VERSION ""

NS_ :

BS_:

BU_:

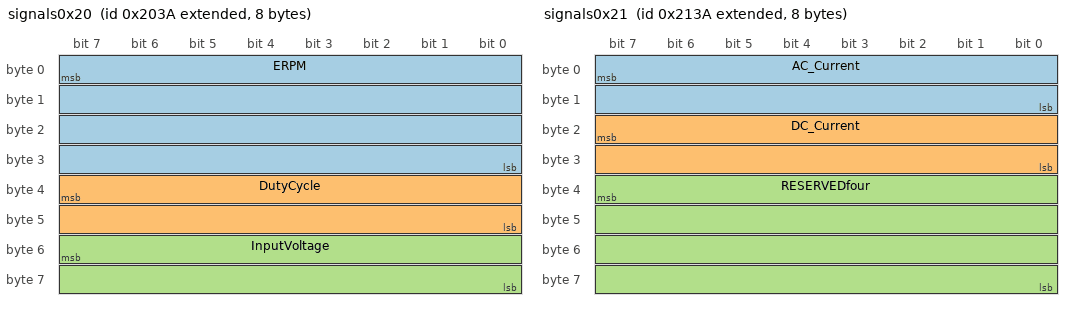
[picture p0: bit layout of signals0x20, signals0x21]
BO_ 2147491898 signals0x20: 8 Vector__XXX
	SG_ ERPM : 7|32@0+ (1,0) [-2147483648|2147483647] "ERPM" Vector__XXX
	SG_ DutyCycle : 39|16@0+ (0.1,0) [-3276.8|3276.7] "%" Vector__XXX
	SG_ InputVoltage : 55|16@0+ (1,0) [-32768|32767] "V" Vector__XXX

BO_ 2147492154 signals0x21: 8 Vector__XXX
	SG_ AC_Current : 7|16@0+ (0.1,0) [-3276.8|3276.7] "Apk" Vector__XXX
	SG_ DC_Current : 23|16@0+ (0.1,0) [-3276.8|3276.7] "Adc" Vector__XXX
	SG_ RESERVEDfour : 39|32@0+ (0,0) [0|0] "" Vector__XXX

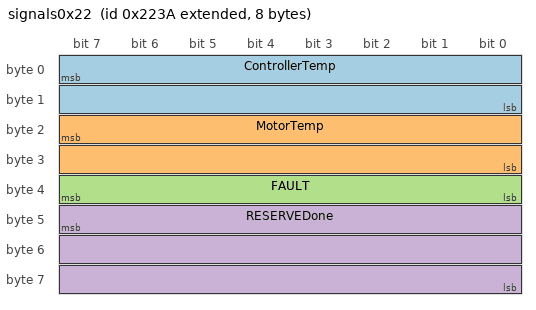
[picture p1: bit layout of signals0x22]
BO_ 2147492410 signals0x22: 8 Vector__XXX
	SG_ ControllerTemp : 7|16@0+ (0.1,0) [-3276.8|3276.7] "°C" Vector__XXX
	SG_ MotorTemp : 23|16@0+ (0.1,0) [-3276.8|3276.7] "°C" Vector__XXX
	SG_ FAULT : 39|8@0+ (1,0) [0|255] "#" Vector__XXX
	SG_ RESERVEDone : 47|24@0+ (0,0) [0|0] "" Vector__XXX

BO_ 2147492666 signals0x23: 8 Vector__XXX
	SG_ FOC_Id : 7|32@0+ (0.01,0) [-2147483.648|2147483.647] "Apk" Vector__XXX
	SG_ FOC_Iq : 39|32@0+ (0.01,0) [-2147483.648|2147483.647] "Apk" Vector__XXX

BO_ 2147492922 signals0x24: 8 Vector__XXX
	SG_ ThrottleSignal : 7|8@0+ (1,0) [-128|127] "%" Vector__XXX
	SG_ BrakeSignal : 15|8@0+ (1,0) [-128|127] "%" Vector__XXX
	SG_ DigitalIn1 : 23|1@0+ (1,0) [0|1] "#" Vector__XXX
	SG_ DigitalIn2 : 22|1@0+ (1,0) [0|1] "#" Vector__XXX
	SG_ DigitalIn3 : 21|1@0+ (1,0) [0|1] "#" Vector__XXX
	SG_ DigitalIn4 : 20|1@0+ (1,0) [0|1] "#" Vector__XXX
	SG_ DigitalOut1 : 19|1@0+ (1,0) [0|1] "#" Vector__XXX
	SG_ DigitalOut2 : 18|1@0+ (1,0) [0|1] "#" Vector__XXX
	SG_ DigitalOut3 : 17|1@0+ (1,0) [0|1] "#" Vector__XXX
	SG_ DigitalOut4 : 16|1@0+ (1,0) [0|1] "#" Vector__XXX
	SG_ DriveEnable : 31|8@0+ (1,0) [0|1] "#" Vector__XXX
	SG_ CapacitorTempLimit : 39|1@0+ (1,0) [0|1] "#" Vector__XXX
	SG_ DCCurrentLimit : 38|1@0+ (1,0) [0|1] "#" Vector__XXX
	SG_ DriveEnableLimit : 37|1@0+ (1,0) [0|1] "#" Vector__XXX
	SG_ IGBTAccelerationTempLimit : 36|1@0+ (1,0) [0|1] "#" Vector__XXX
	SG_ IGBTTempLimit : 35|1@0+ (1,0) [0|1] "#" Vector__XXX
	SG_ InputVoltageLimit : 34|1@0+ (1,0) [0|1] "#" Vector__XXX
	SG_ MotorAccelTempLimit : 33|1@0+ (1,0) [0|1] "#" Vector__XXX
	SG_ MotorTempLimit : 32|1@0+ (1,0) [0|1] "#" Vector__XXX
	SG_ RPMMinLimit : 47|1@0+ (1,0) [0|1] "#" Vector__XXX
	SG_ RPMMaxLimit : 46|1@0+ (1,0) [0|1] "#" Vector__XXX
	SG_ PowerLimit : 45|1@0+ (1,0) [0|1] "#" Vector__XXX
	SG_ RESERVED : 44|5@0+ (1,0) [0|0] "#" Vector__XXX
	SG_ RESERVEDthree : 55|8@0+ (0,0) [0|0] "" Vector__XXX
	SG_ CANMapVersion : 63|8@0+ (1,0) [0|255] "#" Vector__XXX
	SG_ RESERVEDtwo : 44|5@0+ (0,0) [0|0] "" Vector__XXX

CM_ BO_ 2147491898 "ERPM, Duty, Input Voltage";
CM_ SG_ 2147491898 ERPM "Electrical RPM Equation: ERPM = Motor RPM * number of the motor pole pairs.";
CM_ BO_ 2147492154 "AC Current, DC Current, RESERVED";
CM_ SG_ 2147492154 AC_Current "The motor current. The sign of this value represents whether the motor is running(positive) current or regenerating (negative) current.";
CM_ SG_ 2147492154 DC_Current "DC Current: Current on DC side. The sign of this value represents whether the motor is running(positive) current or regenerating (negative) current.";
CM_ SG_ 2147492154 RESERVEDfour "Filled with FF’s. For future use. ";
CM_ SG_ 2147492410 ControllerTemp "Temperature of the inverter semiconductors.";
CM_ SG_ 2147492410 MotorTemp "Temperature of the motor measured by the inverter";
CM_ SG_ 2147492410 FAULT "0x00 : NO FAULTS 0x01 : Overvoltage - The input voltage is higher than the set maximum. 0x02 : Undervoltage - The input voltage is lower than the set minimum. 0x03 : DRV - Transistor or transistor drive error 0x04 : ABS. Overcurrent - The AC current is hi";
CM_ SG_ 2147492666 FOC_Id "FOC algorithm component Id.";
CM_ SG_ 2147492666 FOC_Iq "FOC algorithm component Iq.";
CM_ SG_ 2147492922 ThrottleSignal "Throttle signal derived from analog inputs or CAN2";
CM_ SG_ 2147492922 BrakeSignal "Brake signal derived from analog inputs or CAN2";
CM_ SG_ 2147492922 DigitalIn1 "1: Digital input is active 0: Digital input is inactive";
CM_ SG_ 2147492922 DigitalIn2 "1: Digital input is active 0: Digital input is inactive";
CM_ SG_ 2147492922 DigitalIn3 "1: Digital input is active 0: Digital input is inactive";
CM_ SG_ 2147492922 DigitalIn4 "1: Digital input is active 0: Digital input is inactive";
CM_ SG_ 2147492922 DigitalOut1 "1: Digital output is active. 0: Digital output is inactive";
CM_ SG_ 2147492922 DigitalOut2 "1: Digital output is active. 0: Digital output is inactive";
CM_ SG_ 2147492922 DigitalOut3 "1: Digital output is active. 0: Digital output is inactive";
CM_ SG_ 2147492922 DigitalOut4 "1: Digital output is active. 0: Digital output is inactive";
CM_ SG_ 2147492922 DriveEnable "1: Drive enabled 0: Drive disabled Drive can be enabled/disbled by the digital input or/and via CAN2 interface";
CM_ SG_ 2147492922 CapacitorTempLimit "1: Capacitor temperature limit active 0: Capacitor temperature limit inactive The inverter can limit the output power to not to overheat the internal capacitors. (only valid HW version 3.6 or newer)";
CM_ SG_ 2147492922 DCCurrentLimit "1: DC current limit active 0: DC current limit inactive";
CM_ SG_ 2147492922 DriveEnableLimit "1: Drive enable limit active 0: Drive enable limit inactive Indicates whether the drive enable limitation is active or inactive. Used for software development purposes. For true indication of the drive state please use byte 3, bit 24 of this message.";
CM_ SG_ 2147492922 IGBTAccelerationTempLimit "1: IGBT acceleration limit active 0: IGBT acceleration limit inactive";
CM_ SG_ 2147492922 IGBTTempLimit "1: IGBT temperature limit active 0: IGBT temperature limit inactive";
CM_ SG_ 2147492922 InputVoltageLimit "1: Input voltage limit active 0: Input voltage limit inactive";
CM_ SG_ 2147492922 MotorAccelTempLimit "1: Motor acceleration temperature limit active 0: Motor acceleration temperature limit inactive";
CM_ SG_ 2147492922 MotorTempLimit "1: Motor temperature limit active 0: Motor temperature limit inactive";
CM_ SG_ 2147492922 RPMMinLimit "1: RPM min limit active 0: RPM min limit inactive";
CM_ SG_ 2147492922 RPMMaxLimit "1: RPM max limit active 0: RPM max limit inactive";
CM_ SG_ 2147492922 PowerLimit "1: Power limit by configuration active 0: Power limit by configuration inactive";
CM_ SG_ 2147492922 RESERVEDtwo "Set to 0.";
CM_ SG_ 2147492922 RESERVEDthree "Filled with FF’s. For future use.";
CM_ SG_ 2147492922 CANMapVersion "Indicates the CAN map version. For ex: 23 -> 2,3 (V2,3) ";
CM_ SG_ 2147492410 RESERVEDone "Filled with FF’s. For future use.";
BA_DEF_ SG_  "SPN" INT 0 524287;
BA_DEF_ BO_  "VFrameFormat" ENUM  "StandardCAN","ExtendedCAN","reserved","J1939PG";
BA_DEF_  "DatabaseVersion" STRING ;
BA_DEF_  "BusType" STRING ;
BA_DEF_  "ProtocolType" STRING ;
BA_DEF_  "DatabaseCompiler" STRING ;
BA_DEF_DEF_  "SPN" 0;
BA_DEF_DEF_  "VFrameFormat" "J1939PG";
BA_DEF_DEF_  "DatabaseVersion" "DEMO PLUS";
BA_DEF_DEF_  "BusType" "";
BA_DEF_DEF_  "ProtocolType" "";
BA_DEF_DEF_  "DatabaseCompiler" "";
BA_ "ProtocolType" "J1939";
BA_ "BusType" "CAN";
BA_ "DatabaseCompiler" "CSS ELECTRONICS (WWW.CSSELECTRONICS.COM)";
BA_ "DatabaseVersion" "1.0.0";
BA_ "SPN" SG_ 2364540158 EngineSpeed 190;
